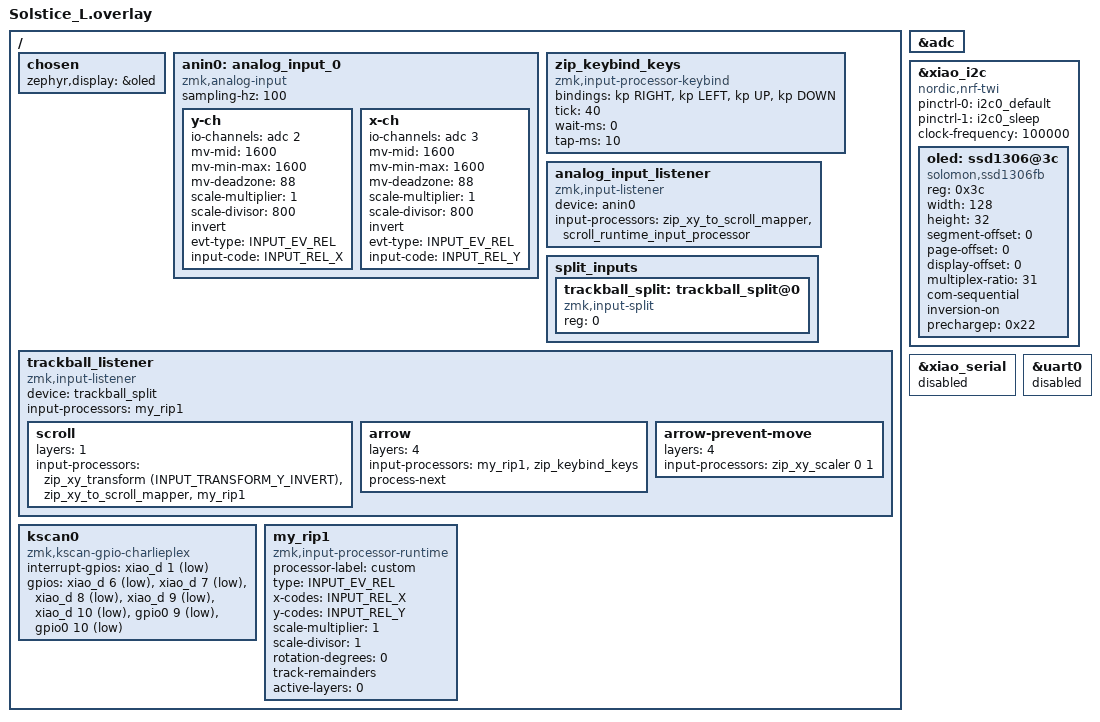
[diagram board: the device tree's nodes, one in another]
#include <dt-bindings/zmk/bt.h>
#include <input/processors.dtsi>
#include <dt-bindings/zmk/input_transform.h>
#include <zephyr/dt-bindings/input/input-event-codes.h>
#include <dt-bindings/zmk/keys.h>
#include <dt-bindings/zmk/pointing.h>
#include "Solstice_pinctrl_L.dtsi"
#include <input/processors/runtime-input-processor.dtsi>

&adc {
	status = "okay";
};

/ {
    chosen {
        zephyr,display = &oled;
    };
    
    anin0: analog_input_0 {
        compatible = "zmk,analog-input";
        sampling-hz = <100>;
        y-ch {
            io-channels = <&adc 2>;
            mv-mid = <1600>;
            mv-min-max = <1600>;
            mv-deadzone = <88>;
            scale-multiplier = <1>;
            scale-divisor = <800>;
            invert;
            evt-type = <INPUT_EV_REL>;
            input-code = <INPUT_REL_X>;
        };
        x-ch {
            io-channels = <&adc 3>;
            mv-mid = <1600>;
            mv-min-max = <1600>;
            mv-deadzone = <88>;
            scale-multiplier = <1>;
            scale-divisor = <800>;
            invert;
            evt-type = <INPUT_EV_REL>;
            input-code = <INPUT_REL_Y>;
        };
    };
    
    zip_keybind_keys: zip_keybind_keys {
        compatible = "zmk,input-processor-keybind";
        #input-processor-cells = <0>;
        bindings = <&kp RIGHT>,
                   <&kp LEFT>,
                   <&kp UP>,
                   <&kp DOWN>;
        tick = <40>;
        wait-ms = <0>;
        tap-ms = <10>;
    };

    analog_input_listener {
        status = "okay";
        compatible = "zmk,input-listener";
        device = <&anin0>;

        input-processors = <&zip_xy_to_scroll_mapper &scroll_runtime_input_processor>;

        // input-processors = <&zip_xy_to_scroll_mapper>;
        
        // arrow {
        //     layers = <1>;
        //     input-processors = <&zip_keybind_keys>;
        //     process-next;
        // };
        
        // arrow-prevent-move {
        //     layers = <1>;
        //     input-processors = <&zip_xy_scaler 0 1>;
        // };
    };

    split_inputs {
        #address-cells = <1>;
        #size-cells = <0>;

        trackball_split: trackball_split@0 {
            compatible = "zmk,input-split";
            reg = <0>;
        };
    };

    trackball_listener: trackball_listener {
        compatible = "zmk,input-listener";
        status = "okay";
        device = <&trackball_split>;
        // input-processors = <&zip_temp_layer 3 700>;
        input-processors = <&my_rip1>;

        scroll {
            layers = <1>;
            // input-processors = <&zip_xy_transform (INPUT_TRANSFORM_Y_INVERT)>, <&zip_xy_scaler 1 16>, <&zip_xy_to_scroll_mapper>;
            input-processors = <&zip_xy_transform (INPUT_TRANSFORM_Y_INVERT)>, 
                               <&zip_xy_to_scroll_mapper>, 
                               <&my_rip1>;
        };
        
        arrow {
            layers = <4>;
            input-processors = <&my_rip1>,
                               <&zip_keybind_keys>;
            process-next;
        };
        
        arrow-prevent-move {
            layers = <4>;
            input-processors = <&zip_xy_scaler 0 1>;
        };
    };

    kscan0: kscan0 {
        compatible = "zmk,kscan-gpio-charlieplex";
        interrupt-gpios = <&xiao_d 1 (GPIO_ACTIVE_LOW)>;
        gpios
            = <&xiao_d 6 (GPIO_ACTIVE_LOW)>
            , <&xiao_d 7 (GPIO_ACTIVE_LOW)>
            , <&xiao_d 8 (GPIO_ACTIVE_LOW)>
            , <&xiao_d 9 (GPIO_ACTIVE_LOW)>
            , <&xiao_d 10 (GPIO_ACTIVE_LOW)>
            , <&gpio0 9 GPIO_ACTIVE_LOW>
            , <&gpio0 10 GPIO_ACTIVE_LOW>
            ;
    };
    
    my_rip1: my_rip1 {
		compatible = "zmk,input-processor-runtime";
		processor-label = "custom";
		type = <INPUT_EV_REL>;
		x-codes = <INPUT_REL_X>;
		y-codes = <INPUT_REL_Y>;
		scale-multiplier = <1>;
		scale-divisor = <1>;
		rotation-degrees = <0>;
		track-remainders;

		// Optional: Temp-layer layer default settings
		// temp-layer-enabled;  // Enable temp-layer by default
		// temp-layer = <1>;  // Default to layer 1
		// temp-layer-activation-delay-ms = <100>;  // 100ms activation delay
		// temp-layer-deactivation-delay-ms = <500>;  // 500ms deactivation delay

		// Optional: Active layers configuration
		// Bitmask of layers where processor should be active (0 = all layers)
		// Each bit represents a layer: bit 0 = layer 0, bit 1 = layer 1, etc.
		// Example: active-layers = <0x00000003> activates on layers 0 and 1 only
		active-layers = <0>;  // Default: active on all layers

		// Optional: Performance optimization
		// temp-layer-transparent-behavior = <&trans>;
		// temp-layer-kp-behavior = <&kp>;
		// temp-layer-keep-keycodes = <LEFT_CONTROL LEFT_SHIFT LEFT_ALT LEFT_GUI RIGHT_CONTROL RIGHT_SHIFT RIGHT_ALT RIGHT_GUI>;

		#input-processor-cells = <0>;
	};
};

&xiao_i2c {
    status = "okay";
    compatible = "nordic,nrf-twi";
    pinctrl-0 = <&i2c0_default>;
    pinctrl-1 = <&i2c0_sleep>;
    pinctrl-names = "default", "sleep";
    
    clock-frequency = <100000>; 
    oled: ssd1306@3c {
        compatible = "solomon,ssd1306fb";
        reg = <0x3c>;
        width = <128>;
        height = <32>;
        segment-offset = <0>;
        page-offset = <0>;
        display-offset = <0>;
        multiplex-ratio = <31>;
        // segment-remap;
        // com-invdir;
        com-sequential;
        inversion-on;
        prechargep = <0x22>;
    };
};
  
&xiao_serial { status = "disabled"; };
&uart0 { status = "disabled";};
